AUTOSAR XML (schema 4-2-2)
package /FCADataDefinition/AppDatatypes
  application record data type ADTRRTCSts: category=STRUCTURE
    application record element e_e_time: category=VALUE, type=ADTRRTCTime
    application record element e_e_wakeup_reason: category=VALUE, type=ADTSRTCWakeup
    application record element e_e_wakeup_config: category=VALUE, type=ADTRRTCWakeupConfig
  application record data type ADTRRTCTime: category=STRUCTURE
    6 x application record element, all with category=VALUE, type=ADTSUint8:
      e_e_year  # 0 – 255
      e_e_month  # 1 – 12
      e_e_day  # 1 - 31
      e_e_hour  # 0 - 23
      e_e_minute  # 0 - 59
      e_e_second  # 0 - 59
  application record data type ADTRRTCWakeupConfig: category=STRUCTURE  # Structure contains all the RTC configuration data
    7 x application record element, all with category=VALUE:
      e_e_enable_alarm: type=ADTSUint8  # 1 – enable; 0 - disable
      e_e_enable_timer: type=ADTSUint8  # 1 – enable; 0 - disable
      e_e_timer_second: type=ADTSUint16  # 1 – 65535
      e_e_alarm_weekday: type=ADTSRTCWeekday  # 0 – 6 or 0xFF
      e_e_alarm_day: type=ADTSUint8  # 1 – 31 or 0xFF
      e_e_alarm_hour: type=ADTSUint8  # 0 – 23 or 0xFF
      e_e_alarm_minute: type=ADTSUint8  # 0 – 59 or 0xFF
  app type ADTSRTCWakeup: category=VALUE, compu {0=RTC_NO_WAKEUP (No RTC wakeup), 1=RTC_ALARM_WAKEUP (Wakeup due to RTC alarm only), 2=RTC_TIMER_WAKEUP (Wakeup due to RTC timer only), 3=RTC_ALARM_TIMER_WAKEUP (Wakeup due to both alarm and timer); unit Enum} "RTC Wakeup Types"
  app type ADTSRTCWeekday: category=VALUE, compu {0=RTC_SUNDAY, 1=RTC_MONDAY, 2=RTC_TUESDAY, 3=RTC_WEDNESDAY, 4=RTC_THURSDAY, 5=RTC_FRIDAY, 6=RTC_SATURDAY; unit Enum} "RTC Type for Weekday"
package /FCASWCs/OnBdDevAb/Timers
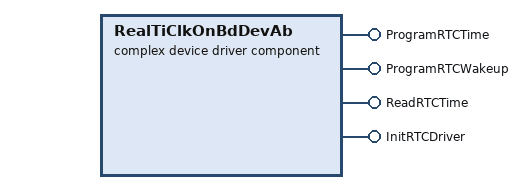
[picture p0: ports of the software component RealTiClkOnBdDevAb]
  complex device driver sw component type RealTiClkOnBdDevAb  # Real Time Clock On Board Device Abstraction (RTC) EVCU is required to wake up to perform scheduled functionality. The RTC interface provides a means of programming the current date/time, alarm and timer for RTC hardware. It’s also used to obtain RTC information during initialization. Supplier will be responsible for initialization of the RTC hardware.
    4 x provide port:
      ProgramRTCTime: provided-interface=ProgramRTCTime
      ProgramRTCWakeup: provided-interface=ProgramRTCWakeup
      ReadRTCTime: provided-interface=ReadRTCTime
      InitRTCDriver: provided-interface=InitRTCDriver
    behavior SwcInternalBehavior_RealTiClkOnBdDevAb: data-type-mapping=ADTtoIDTMapping
      4 x operation invoked event:
        OE_RealTiClkOnBdDevAb_ProgramRTCTime: start-on-event=RealTiClkOnBdDevAb_ProgramRTCTime, operation=ProgramRTCTime.ProgramRTCTime
        OE_RealTiClkOnBdDevAb_ProgramRTCWakeup: start-on-event=RealTiClkOnBdDevAb_ProgramRTCWakeup, operation=ProgramRTCWakeup.ProgramRTCWakeup
        OE_RealTiClkOnBdDevAb_ReadRTCTime: start-on-event=RealTiClkOnBdDevAb_ReadRTCTime, operation=ReadRTCTime.ReadRTCTime
        OE_RealTiClkOnBdDevAb_InitRTCDriver: start-on-event=RealTiClkOnBdDevAb_InitRTCDriver, operation=InitRTCDriver.InitRTCDriver
      4 x runnable:
        RealTiClkOnBdDevAb_InitRTCDriver: symbol=RealTiClkOnBdDevAb_InitRTCDriver_func
        RealTiClkOnBdDevAb_ProgramRTCTime: symbol=RealTiClkOnBdDevAb_ProgramRTCTime_func
        RealTiClkOnBdDevAb_ProgramRTCWakeup: symbol=RealTiClkOnBdDevAb_ProgramRTCWakeup_func
        RealTiClkOnBdDevAb_ReadRTCTime: symbol=RealTiClkOnBdDevAb_ReadRTCTime_func
package /FCASharedInterfaces/IFCOEs/IFPlatform_Srv
  4 x client server interface:
    InitRTCDriver  # Initialize the RTC driver, get wakeup info, and read current time
      operation InitRTCDriver: possible-error=[InitRTCDriver/E_OK, InitRTCDriver/HW_E_FAILED, InitRTCDriver/HW_E_UNAVAILABLE]
        arg RTCStatus: type=ADTRRTCSts, direction=INOUT, server-argument-impl-policy=USE-ARGUMENT-TYPE
      error E_OK: error-code=0  # Request accepted
      error HW_E_FAILED: error-code=63  # Other Failure
      error HW_E_UNAVAILABLE: error-code=9  # A required resource is persistently unavailable. For example, use when a diagnosed hardware failure has disabled an output, or power on reset detected.
    ProgramRTCTime
      operation ProgramRTCTime: possible-error=[ProgramRTCTime/E_OK, ProgramRTCTime/HW_E_FAILED, ProgramRTCTime/HW_E_UNAVAILABLE]
        arg NewTime: type=ADTRRTCTime, direction=INOUT, server-argument-impl-policy=USE-ARGUMENT-TYPE
      error E_OK: error-code=0  # Request Accepted
      error HW_E_FAILED: error-code=63  # Other Failure
      error HW_E_UNAVAILABLE: error-code=9  # A required resource is persistently unavailable. For example, use when a diagnosed hardware failure has disabled an output, or power on reset detected.
    ProgramRTCWakeup
      operation ProgramRTCWakeup: possible-error=[ProgramRTCWakeup/E_OK, ProgramRTCWakeup/HW_E_FAILED, ProgramRTCWakeup/HW_E_UNAVAILABLE]
        arg WakeupConfig: type=ADTRRTCWakeupConfig, direction=INOUT, server-argument-impl-policy=USE-ARGUMENT-TYPE
      error E_OK: error-code=0  # Request Accepted
      error HW_E_FAILED: error-code=63  # Other Failure
      error HW_E_UNAVAILABLE: error-code=9  # A required resource is persistently unavailable. For example, use when a diagnosed hardware failure has disabled an output, or power on reset detected.
    ReadRTCTime
      operation ReadRTCTime: possible-error=[ReadRTCTime/E_OK, ReadRTCTime/HW_E_FAILED, ReadRTCTime/HW_E_UNAVAILABLE]
        arg CurrentTime: type=ADTRRTCTime, direction=INOUT, server-argument-impl-policy=USE-ARGUMENT-TYPE
      error E_OK: error-code=0  # Request Accepted
      error HW_E_FAILED: error-code=63  # Other Failure
      error HW_E_UNAVAILABLE: error-code=9  # A required resource is persistently unavailable. For example, use when a diagnosed hardware failure has disabled an output, or power on reset detected.
package /RTE
  module config Rte
